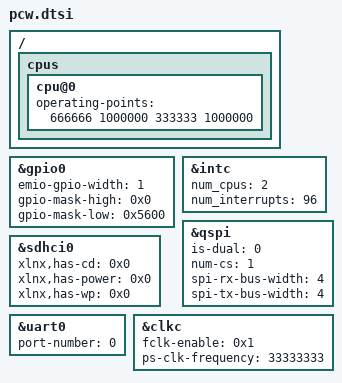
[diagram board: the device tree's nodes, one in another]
/*
 * CAUTION: This file is automatically generated by Xilinx.
 * Version:  
 * Today is: Tue Nov  8 15:11:55 2022
 */


/ {
	cpus {
		cpu@0 {
			operating-points = <666666 1000000 333333 1000000>;
		};
	};
};
&gpio0 {
	emio-gpio-width = <1>;
	gpio-mask-high = <0x0>;
	gpio-mask-low = <0x5600>;
};
&intc {
	num_cpus = <2>;
	num_interrupts = <96>;
};
&qspi {
	is-dual = <0>;
	num-cs = <1>;
	spi-rx-bus-width = <4>;
	spi-tx-bus-width = <4>;
	status = "okay";
};
&sdhci0 {
	status = "okay";
	xlnx,has-cd = <0x0>;
	xlnx,has-power = <0x0>;
	xlnx,has-wp = <0x0>;
};
&uart0 {
	device_type = "serial";
	port-number = <0>;
	status = "okay";
};
&clkc {
	fclk-enable = <0x1>;
	ps-clk-frequency = <33333333>;
};
